# CPPI_DMA_Scheduler register map
Vendor: Texas Instruments
Peripheral module from a debugger description file (folder am335x).
Registers are 32-bit, access per field, no defined reset value unless marked. A register's access mark holds for its fields unless they carry their own. Offsets are as the file gives them; lines under a group give offsets from that group; [hi:lo] are bit positions; {n}, {i} and the like mark numbered series; 'fields as' and 'values as' point back to an identical list; <NAME> marks a mode.

## CPPI_DMA_Scheduler
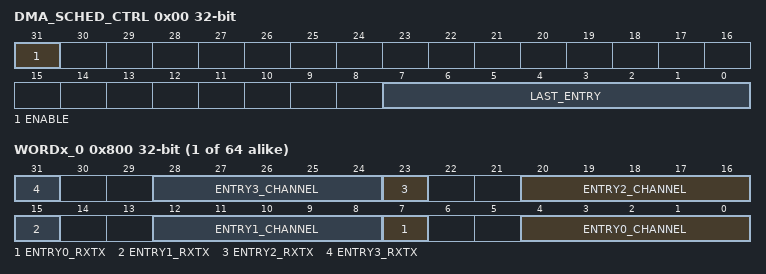
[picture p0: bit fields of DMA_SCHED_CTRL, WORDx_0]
0x00 DMA_SCHED_CTRL rw
  [31] ENABLE — This is the enable bit for the scheduler and is encoded as follows: 0 = scheduler is disabled and will no longer fetch entries from the scheduler table or pass credits to the DMA controller 1 = scheduler is enabled This bit should only be set after the table has been initialized.
  [7:0] LAST_ENTRY — This field indicates the last valid entry in the scheduler table. There are 64 words in the table and there are 4 entries in each word. The table can be programmed with any integer number of entries from 1 to 256. The corresponding encoding for this field is as follows: 0 = 1 entry 1 = 2 entries ... 254 = 255 entries 255 = 256 entries CPPI DMA Scheduler Control Registers
{0x800+4i} WORDx_{i} (i=0..63)
  [8n+7] ENTRY{n}_RXTX wo (n=0..3) — This bit indicates if this entry is for a Tx or an Rx channel and is encoded as follows: 0 = Tx Channel 1 = Rx Channel
  [8n+4:8n] ENTRY{n}_CHANNEL rw (n=0..3) — This field indicates the channel number that is to be given an opportunity to transfer data. If this is a Tx entry, the DMA will be presented with a scheduling ‘credit’ for that exact Tx channel. If this is an Rx entry, the DMA will be presented with a scheduling credit for the Rx FIFO that is associated with this channel. For Rx FIFOs which carry traffic for more than 1 Rx DMA channel, the exact channel number that is given in the Rx credit will actually be the channel number which is currently on the head element of that Rx FIFO, which is not necessarily the channel number given in the scheduler table entry.
